# iostm32f205zx register map
Registers from a debugger description file.
Registers are 32-bit, access not given, no defined reset value unless marked. A register's access mark holds for its fields unless they carry their own. Addresses are absolute; registers are grouped by the start of their names; lines under a group give offsets from that group; [hi:lo] are bit positions; {n}, {i} and the like mark numbered series; 'fields as' and 'values as' point back to an identical list; <NAME> marks a mode.

## Further device data
interrupts=NMI 0x08; HardFault 0x0C; MemManage 0x10; BusFault 0x14; UsageFault 0x18; SVC 0x2C; DebugMon 0x30; PendSV 0x38; SysTick 0x3C; WWDG 0x40; PVD 0x44; TAMPER 0x48; RTC 0x4C; FLASH 0x50; RCC 0x54; EXTI0 0x58; EXTI1 0x5C; EXTI2 0x60; EXTI3 0x64; EXTI4 0x68; DMA1Ch0 0x6C; DMA1Ch1 0x70; DMA1Ch2 0x74; DMA1Ch3 0x78; DMA1Ch4 0x7C; DMA1Ch5 0x80; DMA1Ch6 0x84; ADC1_2 0x88; CAN1_TX 0x8C; CAN1_RX0 0x90; CAN1_RX1 0x94; CAN1_SCE 0x98; EXTI9_5 0x9C; TIM1_BRK_TIM9 0xA0; TIM1_UP_TIM10 0xA4; TIM1_TRG_COM_TIM11 0xA8; TIM1_CC 0xAC; TIM2 0xB0; TIM3 0xB4; TIM4 0xB8; I2C1_EV 0xBC; I2C1_ER 0xC0; I2C2_EV 0xC4; I2C2_ER 0xC8; SPI1 0xCC; SPI2 0xD0; USART1 0xD4; USART2 0xD8; USART3 0xDC; EXTI15_10 0xE0; RTCAlarm 0xE4; TIM8_BRK_TIM12 0xEC; TIM8_UP_TIM13 0xF0; TIM8_TRG_COM_TIM14 0xF4; TIM8_CC 0xF8; DMA_CH7 0xFC; FSMC 0x100; SDIO 0x104; TIM5 0x108; SPI3 0x10C; UART4 0x110; UART5 0x114; TIM6_DAC 0x118; TIM7 0x11C; DMA2Ch0 0x120; DMA2Ch1 0x124; DMA2Ch2 0x128; DMA2Ch3 0x12C; DMA2Ch4 0x130; CAN2_TX 0x13C; CAN2_RX0 0x140; CAN2_RX1 0x144; CAN2_SCE 0x148; DMA2_CH5 0x150; DMA2_CH6 0x154; DMA2_CH7 0x158; USART6 0x15C; I2C3_EV 0x160; I2C3_ER 0x164; OTG_HS_EP1_OUT 0x168; OTG_HS_EP1_IN 0x16C; OTG_HS_WKUP 0x170; OTG_HS 0x174; RNG 0x180

## SFR
0xE000E004 NVIC
  [4:0] INTLINESNUM
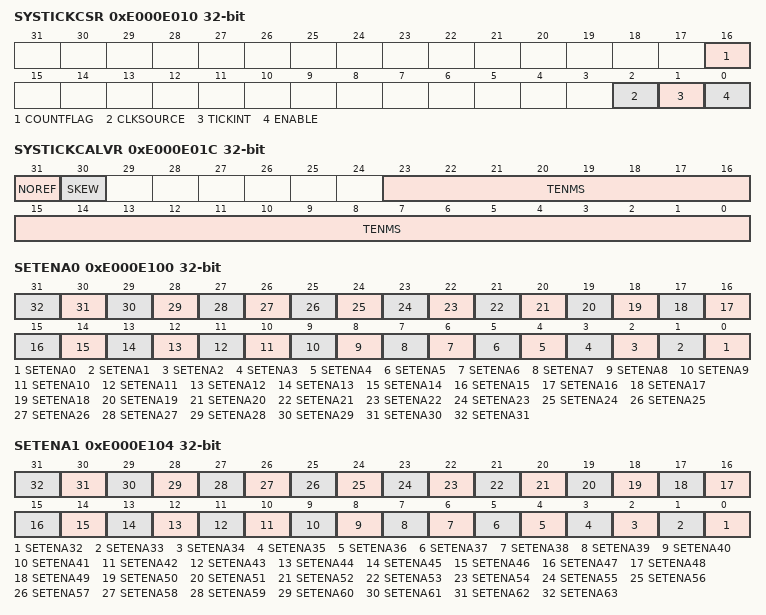
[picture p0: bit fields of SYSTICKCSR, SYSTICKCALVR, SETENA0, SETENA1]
0xE000E010 SYSTICKCSR
  [16] COUNTFLAG, [2] CLKSOURCE, [1] TICKINT, [0] ENABLE
0xE000E014 SYSTICKRVR
  [23:0] RELOAD
0xE000E018 SYSTICKCVR
  [23:0] CURRENT
0xE000E01C SYSTICKCALVR
  [31] NOREF, [30] SKEW, [23:0] TENMS
0xE000E100 SETENA0
  [n] SETENA{n} (n=0..31)
0xE000E104 SETENA1
  [n-32] SETENA{n} (n=32..63)
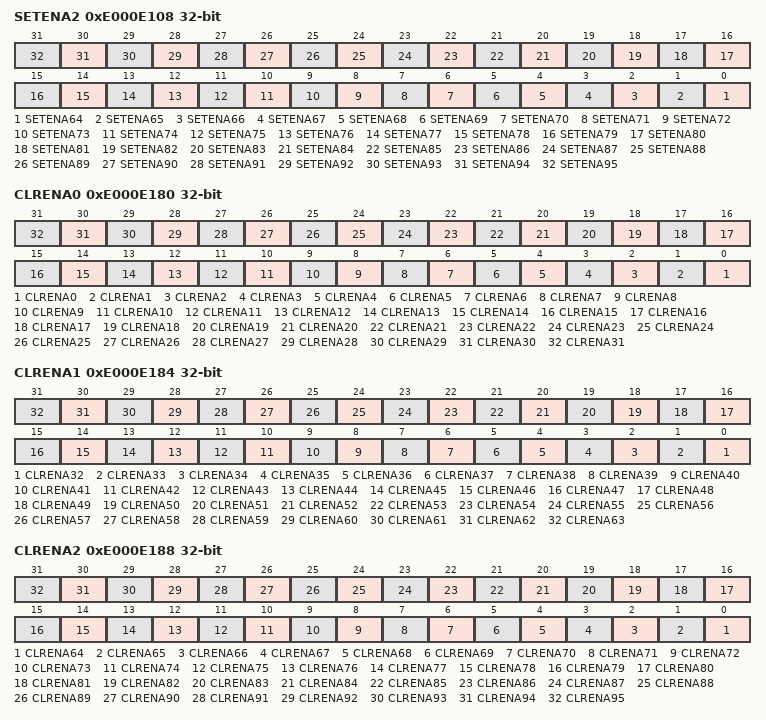
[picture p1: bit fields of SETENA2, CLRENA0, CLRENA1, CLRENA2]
0xE000E108 SETENA2
  [n-64] SETENA{n} (n=64..95)
0xE000E180 CLRENA0
  [n] CLRENA{n} (n=0..31)
0xE000E184 CLRENA1
  [n-32] CLRENA{n} (n=32..63)
0xE000E188 CLRENA2
  [n-64] CLRENA{n} (n=64..95)
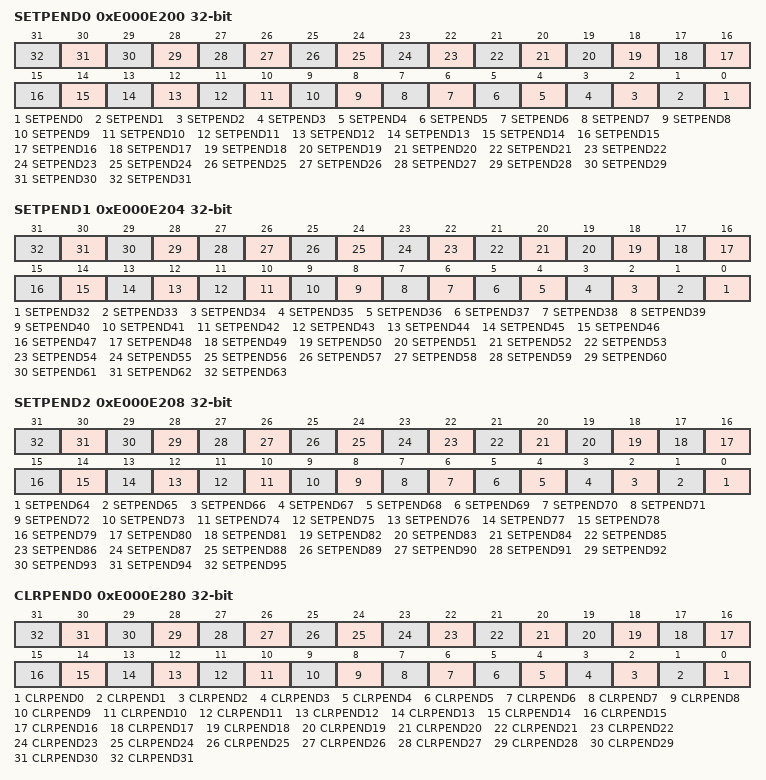
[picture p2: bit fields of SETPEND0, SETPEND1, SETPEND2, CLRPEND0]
0xE000E200 SETPEND0
  [n] SETPEND{n} (n=0..31)
0xE000E204 SETPEND1
  [n-32] SETPEND{n} (n=32..63)
0xE000E208 SETPEND2
  [n-64] SETPEND{n} (n=64..95)
0xE000E280 CLRPEND0
  [n] CLRPEND{n} (n=0..31)
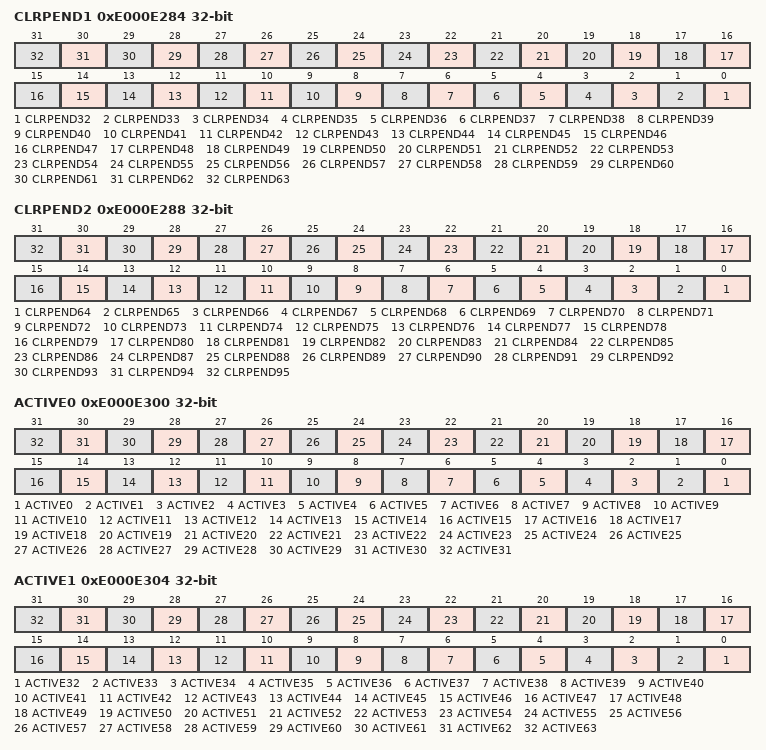
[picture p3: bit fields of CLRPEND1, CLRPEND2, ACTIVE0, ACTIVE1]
0xE000E284 CLRPEND1
  [n-32] CLRPEND{n} (n=32..63)
0xE000E288 CLRPEND2
  [n-64] CLRPEND{n} (n=64..95)
0xE000E300 ACTIVE0
  [n] ACTIVE{n} (n=0..31)
0xE000E304 ACTIVE1
  [n-32] ACTIVE{n} (n=32..63)
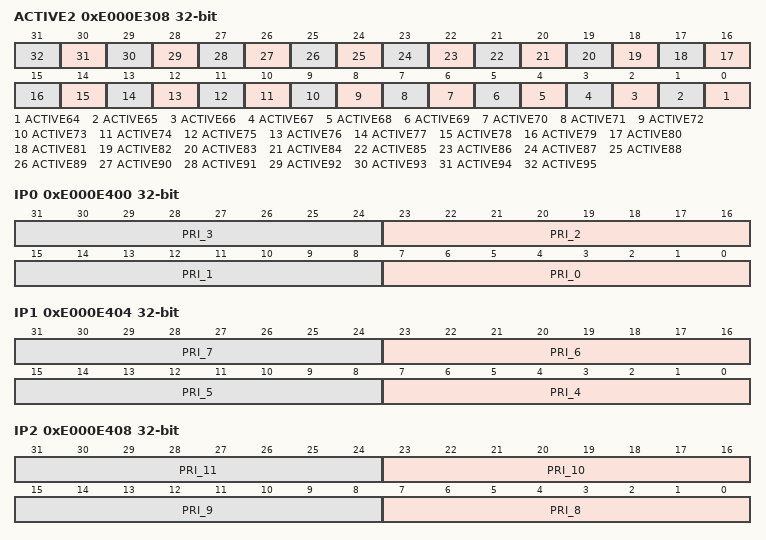
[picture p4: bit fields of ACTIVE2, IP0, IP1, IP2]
0xE000E308 ACTIVE2
  [n-64] ACTIVE{n} (n=64..95)
0xE000E400 IP0
  [8n+7:8n] PRI_{n} (n=0..3)
0xE000E404 IP1
  [8n-25:8n-32] PRI_{n} (n=4..7)
0xE000E408 IP2
  [8n-57:8n-64] PRI_{n} (n=8..11)
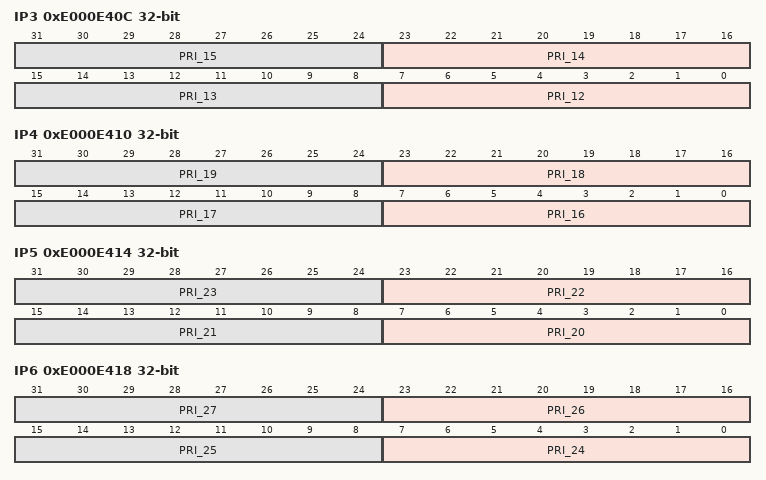
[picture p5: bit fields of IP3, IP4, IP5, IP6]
0xE000E40C IP3
  [8n-89:8n-96] PRI_{n} (n=12..15)
0xE000E410 IP4
  [8n-121:8n-128] PRI_{n} (n=16..19)
0xE000E414 IP5
  [8n-153:8n-160] PRI_{n} (n=20..23)
0xE000E418 IP6
  [8n-185:8n-192] PRI_{n} (n=24..27)
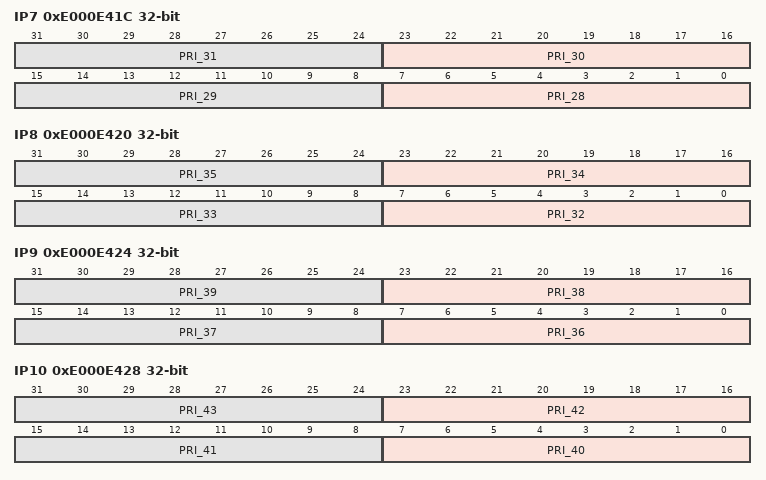
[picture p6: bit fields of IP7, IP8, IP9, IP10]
0xE000E41C IP7
  [8n-217:8n-224] PRI_{n} (n=28..31)
0xE000E420 IP8
  [8n-249:8n-256] PRI_{n} (n=32..35)
0xE000E424 IP9
  [8n-281:8n-288] PRI_{n} (n=36..39)
0xE000E428 IP10
  [8n-313:8n-320] PRI_{n} (n=40..43)
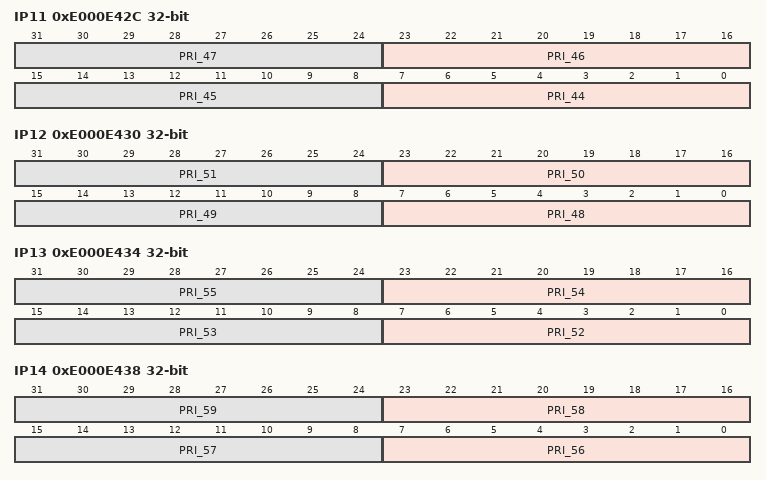
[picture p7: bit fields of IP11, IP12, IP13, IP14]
0xE000E42C IP11
  [8n-345:8n-352] PRI_{n} (n=44..47)
0xE000E430 IP12
  [8n-377:8n-384] PRI_{n} (n=48..51)
0xE000E434 IP13
  [8n-409:8n-416] PRI_{n} (n=52..55)
0xE000E438 IP14
  [8n-441:8n-448] PRI_{n} (n=56..59)
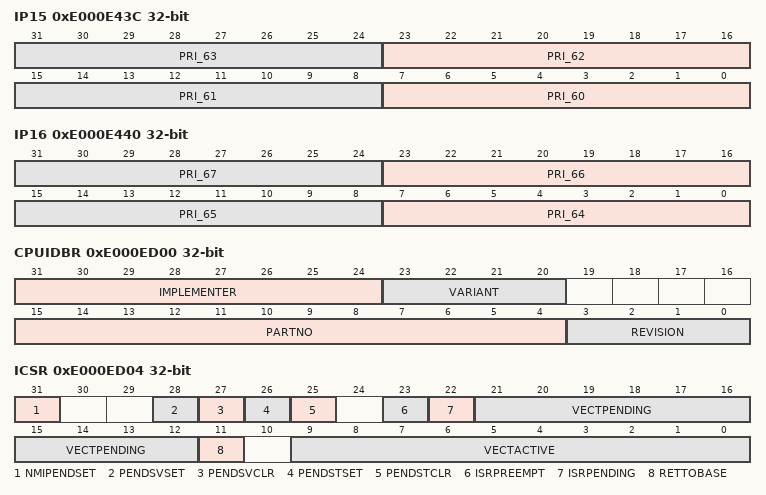
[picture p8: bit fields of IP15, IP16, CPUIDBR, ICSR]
0xE000E43C IP15
  [8n-473:8n-480] PRI_{n} (n=60..63)
0xE000E440 IP16
  [8n-505:8n-512] PRI_{n} (n=64..67)
0xE000ED00 CPUIDBR
  [31:24] IMPLEMENTER, [23:20] VARIANT, [15:4] PARTNO, [3:0] REVISION
0xE000ED04 ICSR
  [31] NMIPENDSET, [28] PENDSVSET, [27] PENDSVCLR, [26] PENDSTSET, [25] PENDSTCLR, [23] ISRPREEMPT, [22] ISRPENDING, [21:12] VECTPENDING, [11] RETTOBASE, [9:0] VECTACTIVE
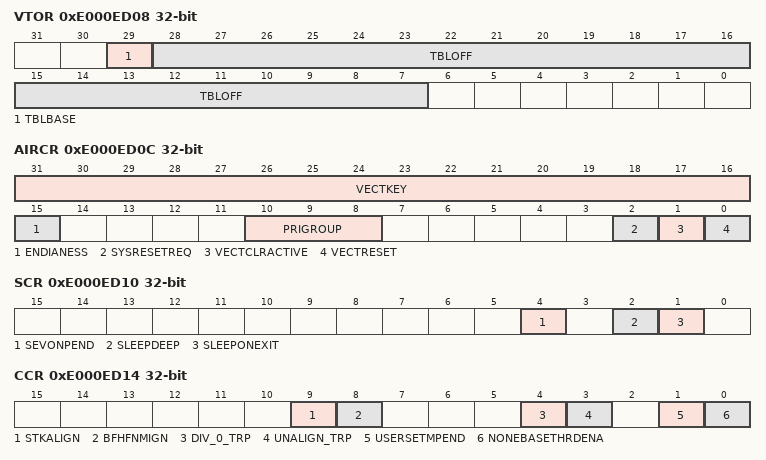
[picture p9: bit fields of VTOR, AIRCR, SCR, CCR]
0xE000ED08 VTOR
  [29] TBLBASE, [28:7] TBLOFF
0xE000ED0C AIRCR
  [31:16] VECTKEY, [15] ENDIANESS, [10:8] PRIGROUP, [2] SYSRESETREQ, [1] VECTCLRACTIVE, [0] VECTRESET
0xE000ED10 SCR
  [4] SEVONPEND, [2] SLEEPDEEP, [1] SLEEPONEXIT
0xE000ED14 CCR
  [9] STKALIGN, [8] BFHFNMIGN, [4] DIV_0_TRP, [3] UNALIGN_TRP, [1] USERSETMPEND, [0] NONEBASETHRDENA
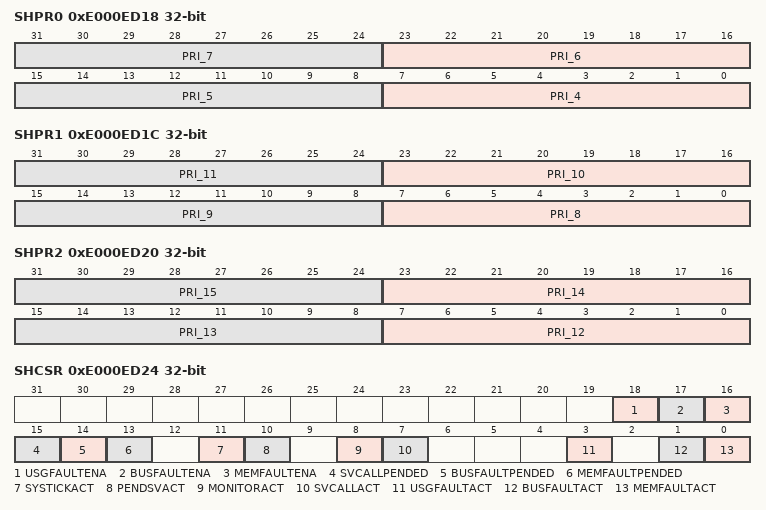
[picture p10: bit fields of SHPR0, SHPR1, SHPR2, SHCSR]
0xE000ED18 SHPR0
  [8n-25:8n-32] PRI_{n} (n=4..7)
0xE000ED1C SHPR1
  [8n-57:8n-64] PRI_{n} (n=8..11)
0xE000ED20 SHPR2
  [8n-89:8n-96] PRI_{n} (n=12..15)
0xE000ED24 SHCSR
  [18] USGFAULTENA, [17] BUSFAULTENA, [16] MEMFAULTENA, [15] SVCALLPENDED, [14] BUSFAULTPENDED, [13] MEMFAULTPENDED, [11] SYSTICKACT, [10] PENDSVACT, [8] MONITORACT, [7] SVCALLACT, [3] USGFAULTACT, [1] BUSFAULTACT, [0] MEMFAULTACT
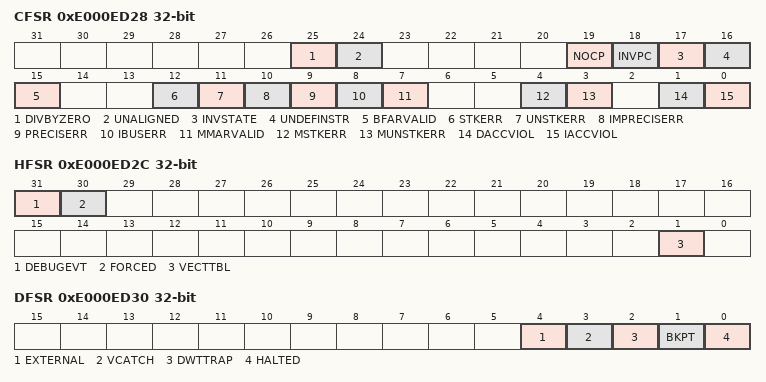
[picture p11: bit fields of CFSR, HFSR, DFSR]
0xE000ED28 CFSR
  [25] DIVBYZERO, [24] UNALIGNED, [19] NOCP, [18] INVPC, [17] INVSTATE, [16] UNDEFINSTR, [15] BFARVALID, [12] STKERR, [11] UNSTKERR, [10] IMPRECISERR, [9] PRECISERR, [8] IBUSERR, [7] MMARVALID, [4] MSTKERR, [3] MUNSTKERR, [1] DACCVIOL, [0] IACCVIOL
0xE000ED2C HFSR
  [31] DEBUGEVT, [30] FORCED, [1] VECTTBL
0xE000ED30 DFSR
  [4] EXTERNAL, [3] VCATCH, [2] DWTTRAP, [1] BKPT, [0] HALTED
0xE000ED34 MMFAR
0xE000ED38 BFAR
0xE000EF00 STIR
  [8:0] INTID
